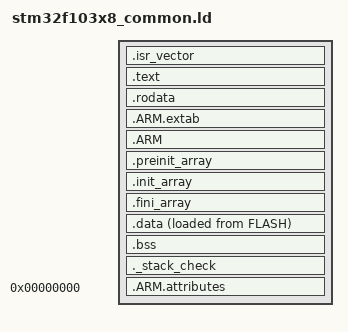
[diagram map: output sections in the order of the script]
/* Sections shared by the app and bring-up images; the including script defines MEMORY, and _settings_start for settings.c */

ENTRY(Reset_Handler)

_estack = ORIGIN(RAM) + LENGTH(RAM);

/* Explicit segments: flash R+X, RAM R+W (.init_array's W flag would otherwise make flash RWX) */
PHDRS
{
  text PT_LOAD FLAGS(5);
  data PT_LOAD FLAGS(6);
}

SECTIONS
{
  .isr_vector :
  {
    . = ALIGN(4);
    KEEP(*(.isr_vector))
    . = ALIGN(4);
  } >FLASH :text

  .text :
  {
    . = ALIGN(4);
    *(.text)
    *(.text*)
    *(.glue_7)
    *(.glue_7t)
    *(.eh_frame)
    KEEP(*(.init))
    KEEP(*(.fini))
    . = ALIGN(4);
    _etext = .;
  } >FLASH

  .rodata :
  {
    . = ALIGN(4);
    *(.rodata)
    *(.rodata*)
    . = ALIGN(4);
  } >FLASH

  .ARM.extab : { *(.ARM.extab* .gnu.linkonce.armextab.*) } >FLASH
  .ARM :
  {
    __exidx_start = .;
    *(.ARM.exidx*)
    __exidx_end = .;
  } >FLASH

  .preinit_array :
  {
    PROVIDE_HIDDEN (__preinit_array_start = .);
    KEEP (*(.preinit_array*))
    PROVIDE_HIDDEN (__preinit_array_end = .);
  } >FLASH
  .init_array :
  {
    PROVIDE_HIDDEN (__init_array_start = .);
    KEEP (*(SORT(.init_array.*)))
    KEEP (*(.init_array*))
    PROVIDE_HIDDEN (__init_array_end = .);
  } >FLASH
  .fini_array :
  {
    PROVIDE_HIDDEN (__fini_array_start = .);
    KEEP (*(SORT(.fini_array.*)))
    KEEP (*(.fini_array*))
    PROVIDE_HIDDEN (__fini_array_end = .);
  } >FLASH

  _sidata = LOADADDR(.data);

  .data :
  {
    . = ALIGN(4);
    _sdata = .;
    *(.data)
    *(.data*)
    . = ALIGN(4);
    _edata = .;
  } >RAM AT> FLASH :data

  .bss :
  {
    . = ALIGN(4);
    _sbss = .;
    __bss_start__ = _sbss;
    *(.bss)
    *(.bss*)
    *(COMMON)
    . = ALIGN(4);
    _ebss = .;
    __bss_end__ = _ebss;
  } >RAM

  /* Fail the link if less than 1 KB is left for the stack */
  ._stack_check (NOLOAD) :
  {
    . = ALIGN(8);
    . = . + 0x400;
  } >RAM

  .ARM.attributes 0 : { *(.ARM.attributes) }
}
